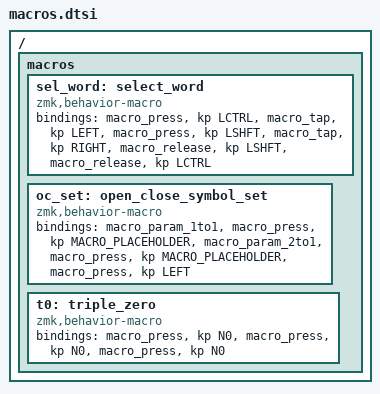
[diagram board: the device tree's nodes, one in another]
/ {
	macros {
		sel_word: select_word {
			compatible = "zmk,behavior-macro";
			#binding-cells = <0>;
			bindings
				= <&macro_press &kp LCTRL>
				, <&macro_tap &kp LEFT>
				, <&macro_press &kp LSHFT>
				, <&macro_tap &kp RIGHT>
				, <&macro_release &kp LSHFT>
				, <&macro_release &kp LCTRL>
				;
		};

		oc_set: open_close_symbol_set {
			compatible = "zmk,behavior-macro";
			#binding-cells = <2>;
			bindings
				= <&macro_param_1to1>
				, <&macro_press &kp MACRO_PLACEHOLDER>
				, <&macro_param_2to1>
				, <&macro_press &kp MACRO_PLACEHOLDER>
				, <&macro_press &kp LEFT>
				;
		};

		t0: triple_zero {
			compatible = "zmk,behavior-macro";
			#binding-cells = <0>;
			bindings
				= <&macro_press &kp N0>
				, <&macro_press &kp N0>
				, <&macro_press &kp N0>
				;
		};
	};
};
